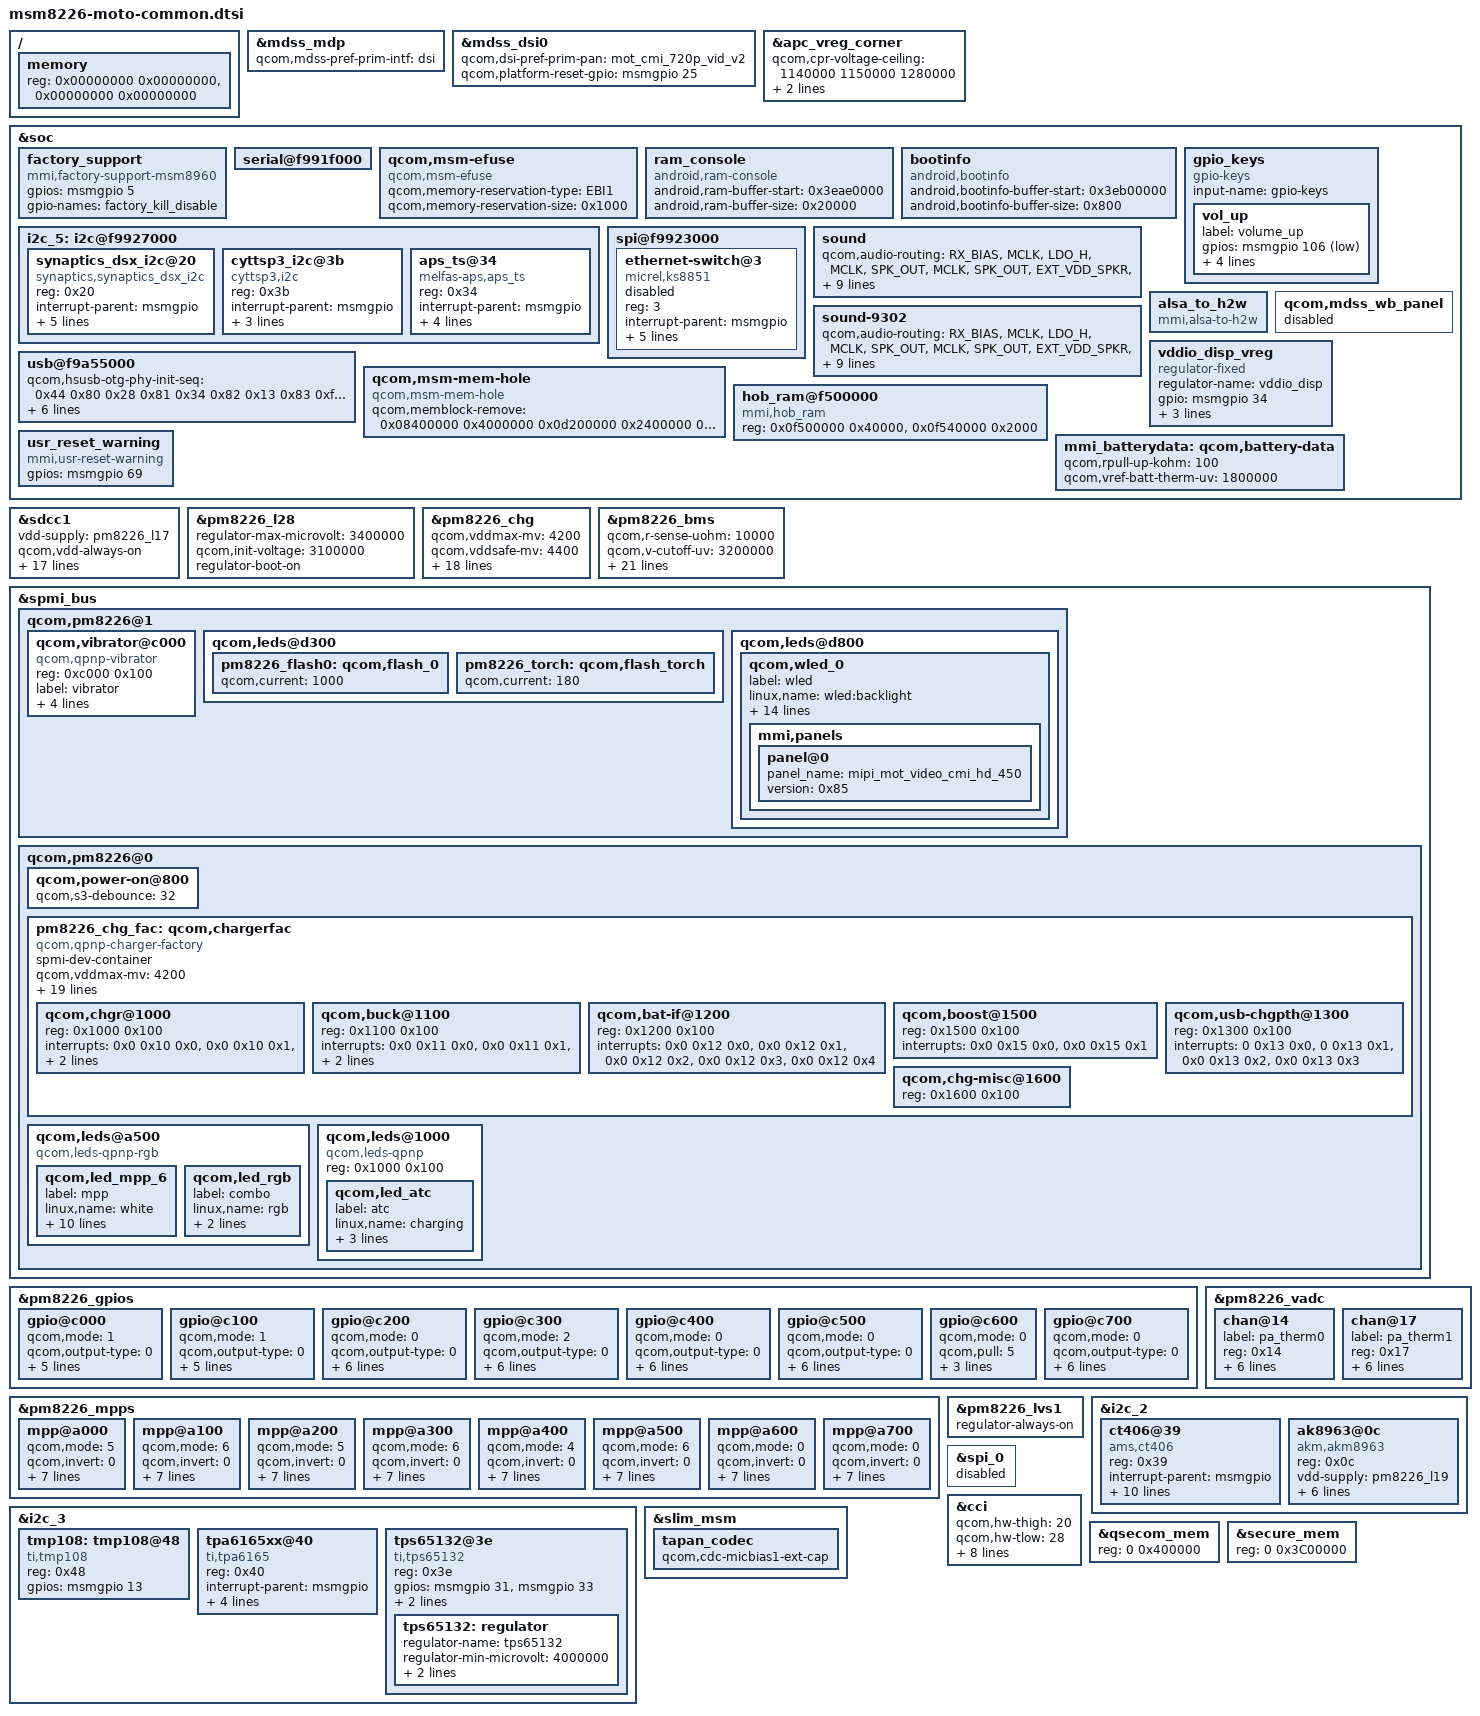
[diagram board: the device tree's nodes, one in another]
/* Copyright (c) 2013, The Linux Foundation. All rights reserved.
 * Copyright (c) 2013 Motorola Mobility LLC
 *
 * This program is free software; you can redistribute it and/or modify
 * it under the terms of the GNU General Public License version 2 and
 * only version 2 as published by the Free Software Foundation.
 *
 * This program is distributed in the hope that it will be useful,
 * but WITHOUT ANY WARRANTY; without even the implied warranty of
 * MERCHANTABILITY or FITNESS FOR A PARTICULAR PURPOSE.  See the
 * GNU General Public License for more details.
 */

/include/ "msm8226-moto-gpiomux.dtsi"
/include/ "carrier-channel-ids.dtsi"

/ {
	memory {
		reg = <0x00000000 0x00000000>,
		      <0x00000000 0x00000000>;
	};
};

&mdss_mdp {
	qcom,mdss-pref-prim-intf = "dsi";
};

&mdss_dsi0 {
	qcom,dsi-pref-prim-pan = <&mot_cmi_720p_vid_v2>;
};

&apc_vreg_corner {
	qcom,cpr-voltage-ceiling = <1140000 1150000 1280000>;
	qcom,cpr-voltage-floor = <1140000 1140000 1140000>;
};

&soc {
	factory_support {
		compatible = "mmi,factory-support-msm8960";

		gpios = <&msmgpio 5 0x2>; /* GPIOF_DIR_OUT | GPIOF_INIT_HIGH */
		gpio-names = "factory_kill_disable";
	};

	serial@f991f000 {
		status = "ok";
	};

	qcom,msm-efuse {
		compatible = "qcom,msm-efuse";
		qcom,memory-reservation-type = "EBI1";
		qcom,memory-reservation-size = <0x1000>; /* 4kb from EBI1 buffer */
	};

	ram_console {
		compatible = "android,ram-console";
		status = "ok";

		android,ram-buffer-start = <0x3eae0000>;
		android,ram-buffer-size = <0x20000>;
	};

	bootinfo {
		compatible = "android,bootinfo";

		android,bootinfo-buffer-start = <0x3eb00000>;
		android,bootinfo-buffer-size = <0x800>;
	};

	i2c_5: i2c@f9927000 {
		synaptics_dsx_i2c@20 {
			compatible = "synaptics,synaptics_dsx_i2c";
			reg = <0x20>;
			interrupt-parent = <&msmgpio>;
			interrupts = <17 0>;
			gpios = <&msmgpio 17 0>, /* IRQ */
				<&msmgpio 16 0>; /* RESET */
			touch_vdd-supply = <&pm8226_l28>;
			synaptics,normal-mode = <1>;
			synaptics,gpio-config;
		};

		cyttsp3_i2c@3b {
			compatible = "cyttsp3,i2c";
			reg = <0x3b>;
			interrupt-parent = <&msmgpio>;
			interrupts = <17 0x0>;
			vdd-supply = <&pm8226_l19>;
			vcc_i2c-supply = <&pm8226_lvs1>;
		};

		aps_ts@34 {
			compatible = "melfas-aps,aps_ts";
			reg = <0x34>;
			interrupt-parent = <&msmgpio>;
			interrupts = <17 0>;
			gpios = <&msmgpio 17 0>, /* IRQ */
				<&msmgpio 16 0>; /* RESET */
			aps_ts,default-product-id = "Falc";
			aps_ts,high-speed-isp;
		};
	};

	gpio_keys {
		compatible = "gpio-keys";
		input-name = "gpio-keys";

		vol_up {
			label = "volume_up";
			gpios = <&msmgpio 106 0x1>;
			linux,input-type = <1>;
			linux,code = <115>;
			gpio-key,wakeup;
			debounce-interval = <15>;
		};
	};

	spi@f9923000 {
		ethernet-switch@3 {
			status = "disabled";
			compatible = "micrel,ks8851";
			reg = <3>;
			interrupt-parent = <&msmgpio>;
			interrupts = <0 115 0>;
			spi-max-frequency = <4800000>;
			rst-gpio = <&msmgpio 114 0>;
			vdd-io-supply = <&pm8226_lvs1>;
			vdd-phy-supply = <&pm8226_lvs1>;
		};
	};

	sound {
		qcom,audio-routing =
			"RX_BIAS", "MCLK",
			"LDO_H", "MCLK",
			"SPK_OUT", "MCLK",
			"SPK_OUT", "EXT_VDD_SPKR",
			"AMIC1", "MIC BIAS1 External",
			"MIC BIAS1 External", "Handset Mic",
			"AMIC2", "MIC BIAS2 External",
			"MIC BIAS2 External", "Headset Mic",
			"AMIC3", "MIC BIAS1 External",
			"MIC BIAS1 External", "ANCRight Headset Mic",
			"AMIC4", "MIC BIAS2 External",
			"MIC BIAS2 External", "ANCLeft Headset Mic";

		qcom,cdc-mclk-gpios = <&pm8226_gpios 1 0>;
		qcom,cdc-vdd-spkr-gpios = <&pm8226_gpios 2 0>;
	};

	sound-9302 {
		qcom,audio-routing =
			"RX_BIAS", "MCLK",
			"LDO_H", "MCLK",
			"SPK_OUT", "MCLK",
			"SPK_OUT", "EXT_VDD_SPKR",
			"AMIC1", "MIC BIAS1 External",
			"MIC BIAS1 External", "Handset Mic",
			"AMIC2", "MIC BIAS2 External",
			"MIC BIAS2 External", "Headset Mic",
			"AMIC3", "MIC BIAS1 External",
			"MIC BIAS1 External", "ANCRight Headset Mic",
			"AMIC4", "MIC BIAS2 External",
			"MIC BIAS2 External", "ANCLeft Headset Mic";

		qcom,cdc-mclk-gpios = <&pm8226_gpios 1 0>;
		qcom,cdc-vdd-spkr-gpios = <&pm8226_gpios 2 0>;
	};

	usb@f9a55000 {
		qcom,hsusb-otg-phy-init-seq =
                        <0x44 0x80 0x28 0x81 0x34 0x82 0x13 0x83 0xffffffff>;
		qcom,hsusb-otg-mode = <3>;
		vbus_otg-supply = <&pm8226_chg_otg>;
		otg,id_flt_gpio = <&msmgpio 111 0x0>;
		otg,id_gnd_gpio = <&msmgpio 112 0x0>;
		id_flt_active_high = <1>;
		id_gnd_active_high = <1>;
	};

	alsa_to_h2w {
		compatible = "mmi,alsa-to-h2w";
	};

	qcom,mdss_wb_panel {
		status = "disabled";
	};

	vddio_disp_vreg: vddio_disp_vreg {
		compatible = "regulator-fixed";
		regulator-name = "vddio_disp";
		gpio = <&msmgpio 34 0x0>;
		parent-supply = <&pm8226_l8>;
		startup-delay-us = <300>;
		enable-active-high;
	};

	qcom,msm-mem-hole {
		compatible = "qcom,msm-mem-hole";
		qcom,memblock-remove = <0x08400000 0x4000000
					0x0d200000 0x2400000
					0x0fa00000 0x500000>; /* Address and Size of Hole */
	};

	hob_ram@f500000 {
		compatible = "mmi,hob_ram";
		reg = <0x0f500000 0x40000>,
		      <0x0f540000 0x2000>;
	};
	usr_reset_warning {
		compatible = "mmi,usr-reset-warning";
		gpios = <&msmgpio 69 0x0>;
	};

	mmi_batterydata: qcom,battery-data {
		qcom,rpull-up-kohm = <100>;
		qcom,vref-batt-therm-uv = <1800000>;

		/include/ "batterydata-ed30-temp.dtsi"
		/include/ "batterydata-ed30-sony.dtsi"
		/include/ "batterydata-ed30-sony-alt.dtsi"
		/include/ "batterydata-ed30-lg.dtsi"
	};
};

&sdcc1 {
	vdd-supply = <&pm8226_l17>;
	qcom,vdd-always-on;
	qcom,vdd-lpm-sup;
	qcom,vdd-voltage-level = <2950000 2950000>;
	qcom,vdd-current-level = <800 500000>;

	vdd-io-supply = <&pm8226_l6>;
	qcom,vdd-io-always-on;
	qcom,vdd-io-voltage-level = <1800000 1800000>;
	qcom,vdd-io-current-level = <250 154000>;

	qcom,pad-pull-on = <0x0 0x3 0x3>; /* no-pull, pull-up, pull-up */
	qcom,pad-pull-off = <0x0 0x3 0x3>; /* no-pull, pull-up, pull-up */
	qcom,pad-drv-on = <0x4 0x4 0x4>; /* 16mA, 10mA, 10mA */
	qcom,pad-drv-off = <0x0 0x0 0x0>; /* 2mA, 2mA, 2mA */

	qcom,clk-rates = <400000 25000000 50000000 100000000 200000000>;
	qcom,sup-voltages = <2950 2950>;

	qcom,bus-speed-mode = "HS200_1p8v", "DDR_1p8v";
	qcom,nonremovable;
	qcom,emmc;

	status = "ok";
};

&pm8226_l28 {
	regulator-max-microvolt = <3400000>;
	qcom,init-voltage = <3100000>;
	regulator-boot-on;
};

&pm8226_chg {
	qcom,vddmax-mv = <4200>;
	qcom,vddsafe-mv = <4400>;
	qcom,vinmin-mv = <4300>;
	qcom,vbatdet-delta-mv = <150>;
	qcom,ibatmax-ma = <2000>;
	qcom,ibatterm-ma = <100>;
	qcom,ibatsafe-ma = <3250>;
	qcom,thermal-mitigation = <1500 700 600 325>;
	qcom,tchg-mins = <512>;
	qcom,warm-bat-decidegc = <450>;
	qcom,cool-bat-decidegc = <0>;
	qcom,warm-bat-mv = <4000>;
	qcom,cool-bat-mv = <4000>;
	qcom,ibatmax-warm-ma = <2000>;
	qcom,ibatmax-cool-ma = <2000>;
	qcom,batt-hot-percentage = <25>;
	qcom,batt-cold-percentage = <80>;
	qcom,step-charge-voltage = <4200>;
	qcom,step-charge-current = <1130>;
	qcom,float-charge-timer = <1800>;
};

&pm8226_bms {
	qcom,r-sense-uohm = <10000>;
	qcom,v-cutoff-uv = <3200000>;
	qcom,max-voltage-uv = <4200000>;
	qcom,r-conn-mohm = <0>;
	qcom,shutdown-soc-valid-limit = <100>;
	qcom,adjust-soc-low-threshold = <15>;
	qcom,use-ocv-thresholds = <0>;
	qcom,low-soc-calculate-soc-threshold = <15>;
	qcom,low-soc-calculate-soc-ms = <5000>;
	qcom,calculate-soc-ms = <20000>;
	qcom,chg-term-ua = <100000>;
	qcom,batt-type = <0>;
	qcom,tm-temp-margin = <5000>;
	qcom,low-ocv-correction-limit-uv = <100>;
	qcom,high-ocv-correction-limit-uv = <50>;
	qcom,hold-soc-est = <3>;
	qcom,low-voltage-threshold = <3220000>;
	qcom,enable-fcc-learning = <1>;
	qcom,min-fcc-learning-soc = <20>;
	qcom,fcc-resolution = <10>;
	qcom,min-fcc-ocv-pc = <20>;
	qcom,min-fcc-learning-samples = <4>;
	qcom,battery-data = <&mmi_batterydata>;
};

&spmi_bus {
	qcom,pm8226@1 {
		qcom,vibrator@c000 {
			status = "okay";
			compatible = "qcom,qpnp-vibrator";
			reg = <0xc000 0x100>;
			label = "vibrator";
			qcom,vib-timeout-ms = <30000>;
			qcom,vib-vtg-level-mV = <1800>;
			qcom,vib-vtg-level-mV-haptic = <2800>;
			qcom,vib-boot-up-vibe-ms = <100>;
		};

		qcom,leds@d300 {
			status = "okay";
			pm8226_flash0: qcom,flash_0 {
				qcom,current = <1000>;
			};

			pm8226_torch: qcom,flash_torch {
				qcom,current = <180>;
			};
		};

		qcom,leds@d800 {
			status = "okay";
			qcom,wled_0 {
				label = "wled";
				linux,name = "wled:backlight";
				linux,default-trigger = "bkl-trigger";
				qcom,cs-out-en;
				qcom,op-fdbck = <1>;
				qcom,default-state = "off";
				qcom,max-current = <18>;
				qcom,ctrl-delay-us = <0>;
				qcom,boost-curr-lim = <0x03>;
				qcom,max-boost-duty = <0x02>;
				qcom,mod-scheme = <0x00>;
				qcom,cp-sel = <0>;
				qcom,switch-freq = <0x0b>;
				qcom,ovp-val = <2>;
				qcom,num-strings = <1>;
				qcom,id = <0>;
				mmi,panels {
					panel@0 {
						panel_name = "mipi_mot_video_cmi_hd_450";
						version = <0x85>;
					};
				};
			};
		};
	};

	qcom,pm8226@0 {

		qcom,power-on@800 {
			qcom,s3-debounce = <32>;
		};

		pm8226_chg_fac: qcom,chargerfac {
			spmi-dev-container;
			compatible = "qcom,qpnp-charger-factory";
			#address-cells = <1>;
			#size-cells = <1>;
			status = "ok";

			qcom,vddmax-mv = <4200>;
			qcom,vddsafe-mv = <4400>;
			qcom,vinmin-mv = <4300>;
			qcom,vbatdet-delta-mv = <150>;
			qcom,ibatmax-ma = <2000>;
			qcom,ibatterm-ma = <100>;
			qcom,ibatsafe-ma = <3250>;
			qcom,thermal-mitigation = <1500 700 600 325>;
			qcom,resume-soc = <99>;
			qcom,tchg-mins = <150>;
			qcom,chg-vadc = <&pm8226_vadc>;
			qcom,chg-adc_tm = <&pm8226_adc_tm>;
			qcom,ibatmax-warm-ma = <2000>;
			qcom,warm-bat-decidegc = <450>;
			qcom,warm-bat-mv = <4000>;
			qcom,cool-bat-decidegc = <10>;
			qcom,cool-bat-mv = <4000>;
			qcom,ibatmax-cool-ma = <2000>;
			qcom,batt-hot-percentage = <25>;
			qcom,batt-cold-percentage = <80>;

			qcom,chgr@1000 {
				status = "ok";
				reg = <0x1000 0x100>;
				interrupts =	<0x0 0x10 0x0>,
						<0x0 0x10 0x1>,
						<0x0 0x10 0x2>,
						<0x0 0x10 0x3>,
						<0x0 0x10 0x4>,
						<0x0 0x10 0x5>,
						<0x0 0x10 0x6>,
						<0x0 0x10 0x7>;

				interrupt-names =	"vbat-det-lo",
							"vbat-det-hi",
							"chgwdog",
							"state-change",
							"trkl-chg-on",
							"fast-chg-on",
							"chg-failed",
							"chg-done";
			};

			qcom,buck@1100 {
				status = "ok";
				reg = <0x1100 0x100>;
				interrupts =	<0x0 0x11 0x0>,
						<0x0 0x11 0x1>,
						<0x0 0x11 0x2>,
						<0x0 0x11 0x3>,
						<0x0 0x11 0x4>,
						<0x0 0x11 0x5>,
						<0x0 0x11 0x6>;

				interrupt-names =	"vbat-ov",
							"vreg-ov",
							"overtemp",
							"vchg-loop",
							"ichg-loop",
							"ibat-loop",
							"vdd-loop";
			};

			qcom,bat-if@1200 {
				status = "ok";
				reg = <0x1200 0x100>;
				interrupts =	<0x0 0x12 0x0>,
						<0x0 0x12 0x1>,
						<0x0 0x12 0x2>,
						<0x0 0x12 0x3>,
						<0x0 0x12 0x4>;

				interrupt-names =	"batt-pres",
							"bat-temp-ok",
							"bat-fet-on",
							"vcp-on",
							"psi";
			};

			qcom,boost@1500 {
				status = "ok";
				reg = <0x1500 0x100>;
				interrupts =	<0x0 0x15 0x0>,
						<0x0 0x15 0x1>;

				interrupt-names =	"boost-pwr-ok",
							"limit-error";
			};


			qcom,usb-chgpth@1300 {
				status = "ok";
				reg = <0x1300 0x100>;
				interrupts =	<0 0x13 0x0>,
						<0 0x13 0x1>,
						<0x0 0x13 0x2>,
						<0x0 0x13 0x3>;

				interrupt-names =	"coarse-det-usb",
							"usbin-valid",
							"chg-gone",
							"usb-ocp";
			};

			qcom,chg-misc@1600 {
				status = "ok";
				reg = <0x1600 0x100>;
			};
		};

		qcom,leds@a500 {
			compatible = "qcom,leds-qpnp-rgb";
			status = "okay";
			qcom,led_mpp_6 {
				label = "mpp";
				linux,name = "white";
				linux,default-trigger = "none";
				qcom,default-state = "off";
				qcom,max-current = <40>;
				qcom,current-setting = <5>;
				qcom,id = <6>;
				qcom,mode = "pwm";
				qcom,source-sel = <10>;
				qcom,mode-ctrl = <0x60>;
				qcom,pwm-channel = <5>;
				qcom,pwm-us = <1000>;
			};

		qcom,led_rgb {
				label = "combo";
				linux,name = "rgb";
				qcom,max-current = <12>;
				qcom,id = <9>;
			};
		};

		qcom,leds@1000 {
			status = "ok";
			reg = <0x1000 0x100>;
			compatible = "qcom,leds-qpnp";
			qcom,led_atc {
				label = "atc";
				linux,name = "charging";
				qcom,max-current = <40>;
				qcom,id = <8>;
				qcom,mode = <2>;
			};
		};
	};
};

&pm8226_gpios {
	gpio@c000 { /* GPIO 1 */
		/* XO_PMIC_CDC_MCLK enable for tapan codec */
		qcom,mode = <1>;		/* Digital output */
		qcom,output-type = <0>;	/* CMOS logic */
		qcom,pull = <5>;		/* QPNP_PIN_PULL_NO*/
		qcom,vin-sel = <2>;		/* QPNP_PIN_VIN2 */
		qcom,out-strength = <3>;/* QPNP_PIN_OUT_STRENGTH_HIGH */
		qcom,src-sel = <2>;		/* QPNP_PIN_SEL_FUNC_1 */
		qcom,master-en = <1>;	/* Enable GPIO */
	};

	gpio@c100 { /* GPIO 2 */
		qcom,mode = <1>;
		qcom,output-type = <0>;
		qcom,pull = <5>;
		qcom,vin-sel = <2>;
		qcom,out-strength = <3>;
		qcom,src-sel = <2>;
		qcom,master-en = <1>;
	};

	gpio@c200 { /* GPIO 3 */
		/* unused, force low power state */
		qcom,mode = <0>;
		qcom,output-type = <0>;
		qcom,invert = <0>;
		qcom,pull = <4>;
		qcom,vin-sel = <0>;
		qcom,out-strength = <1>;
		qcom,src-sel = <0>;
		qcom,master-en = <1>;
	};

	gpio@c300 { /* GPIO 4 */
		/* BATT_UIM_ALARM */
		qcom,mode = <2>;
		qcom,output-type = <0>;
		qcom,invert = <0>;
		qcom,pull = <4>;
		qcom,vin-sel = <3>;
		qcom,out-strength = <1>;
		qcom,src-sel = <2>;
		qcom,master-en = <1>;
	};

	gpio@c400 { /* GPIO 5 */
		/* unused, force low power state */
		qcom,mode = <0>;
		qcom,output-type = <0>;
		qcom,invert = <0>;
		qcom,pull = <4>;
		qcom,vin-sel = <0>;
		qcom,out-strength = <1>;
		qcom,src-sel = <0>;
		qcom,master-en = <1>;
	};

	gpio@c500 { /* GPIO 6 */
		/* LCD_CABC_WLED */
		qcom,mode = <0>;
		qcom,output-type = <0>;
		qcom,invert = <0>;
		qcom,pull = <5>;
		qcom,vin-sel = <3>;
		qcom,out-strength = <1>;
		qcom,src-sel = <2>;
		qcom,master-en = <1>;
	};

	gpio@c600 { /* GPIO 7 */
		/* TX_GTR_THRESH FUNC for PA_ON_NOFLASH */
		qcom,mode = <0>;		/* Digital input */
		qcom,pull = <5>;		/* QPNP_PIN_PULL_NO*/
		qcom,vin-sel = <3>;		/* QPNP_PIN_VIN3 L6 1.8V */
		qcom,src-sel = <2>;		/* QPNP_PIN_SEL_FUNC_1 */
		qcom,master-en = <1>;	/* Enable GPIO */
	};

	gpio@c700 { /* GPIO 8 */
		/* unused, force low power state */
		qcom,mode = <0>;
		qcom,output-type = <0>;
		qcom,invert = <0>;
		qcom,pull = <4>;
		qcom,vin-sel = <0>;
		qcom,out-strength = <1>;
		qcom,src-sel = <0>;
		qcom,master-en = <1>;
	};
};

&pm8226_mpps {
	mpp@a000 { /* MPP 1 */
		/* MSM_PX config */
		qcom,mode = <5>;
		qcom,invert = <0>;
		qcom,pull = <0>;
		qcom,vin-sel = <2>;
		qcom,src-sel = <1>;
		qcom,master-en = <1>;
		qcom,aout-ref = <0>;
		qcom,ain-route = <0>;
		qcom,cs-out = <0>;
	};

	mpp@a100 { /* MPP 2 */
		/* HR_LED_SINK config */
		qcom,mode = <6>;
		qcom,invert = <0>;
		qcom,pull = <0>;
		qcom,vin-sel = <0>;
		qcom,src-sel = <12>;
		qcom,master-en = <1>;
		qcom,aout-ref = <0>;
		qcom,ain-route = <0>;
		qcom,cs-out = <0>;
	};

	mpp@a200 { /* MPP 3 */
		/* VREF_LDO config */
		qcom,mode = <5>;
		qcom,invert = <0>;
		qcom,pull = <0>;
		qcom,vin-sel = <2>;
		qcom,src-sel = <1>;
		qcom,master-en = <1>;
		qcom,aout-ref = <0>;
		qcom,ain-route = <0>;
		qcom,cs-out = <0>;
	};

	mpp@a300 { /* MPP 4 */
		/* LED1_SINK config */
		qcom,mode = <6>;
		qcom,invert = <0>;
		qcom,pull = <0>;
		qcom,vin-sel = <0>;
		qcom,src-sel = <8>;
		qcom,master-en = <1>;
		qcom,aout-ref = <0>;
		qcom,ain-route = <0>;
		qcom,cs-out = <0>;
	};

	mpp@a400 { /* MPP 5 */
		/* PA_THERM0 config */
		qcom,mode = <4>;
		qcom,invert = <0>;
		qcom,pull = <0>;
		qcom,vin-sel = <0>;
		qcom,src-sel = <1>;
		qcom,master-en = <1>;
		qcom,aout-ref = <0>;
		qcom,ain-route = <0>;
		qcom,cs-out = <0>;
	};

	mpp@a500 { /* MPP 6 */
		/* LED2_SINK config */
		qcom,mode = <6>;
		qcom,invert = <0>;
		qcom,pull = <0>;
		qcom,vin-sel = <0>;
		qcom,src-sel = <10>;
		qcom,master-en = <1>;
		qcom,aout-ref = <0>;
		qcom,ain-route = <0>;
		qcom,cs-out = <0>;
	};

	mpp@a600 { /* MPP 7 */
		/* unused, force low power state */
		qcom,mode = <0>;
		qcom,invert = <0>;
		qcom,pull = <0>;
		qcom,vin-sel = <0>;
		qcom,src-sel = <0>;
		qcom,master-en = <0>;
		qcom,aout-ref = <0>;
		qcom,ain-route = <0>;
		qcom,cs-out = <0>;
	};

	mpp@a700 { /* MPP 8 */
		/* unused, force low power state */
		qcom,mode = <0>;
		qcom,invert = <0>;
		qcom,pull = <0>;
		qcom,vin-sel = <0>;
		qcom,src-sel = <0>;
		qcom,master-en = <0>;
		qcom,aout-ref = <0>;
		qcom,ain-route = <0>;
		qcom,cs-out = <0>;
	};
};

&pm8226_vadc {
	chan@14 {
		label = "pa_therm0";
		reg = <0x14>;
		qcom,decimation = <0>;
		qcom,pre-div-channel-scaling = <0>;
		qcom,calibration-type = "ratiometric";
		qcom,scale-function = <2>;
		qcom,hw-settle-time = <2>;
		qcom,fast-avg-setup = <0>;
	};

	chan@17 {
		label = "pa_therm1";
		reg = <0x17>;
		qcom,decimation = <0>;
		qcom,pre-div-channel-scaling = <0>;
		qcom,calibration-type = "ratiometric";
		qcom,scale-function = <2>;
		qcom,hw-settle-time = <2>;
		qcom,fast-avg-setup = <0>;
	};
};

&pm8226_lvs1 {
	regulator-always-on;
};

&i2c_2 {
	status = "ok";

	ct406@39 {
		compatible = "ams,ct406";
		reg = <0x39>;
		interrupt-parent = <&msmgpio>;
		interrupts = <65 0x2>;
		gpios = <&msmgpio 65 0>; /* IRQ */
		vdd-supply = <&pm8226_l19>;
		ams,prox-samples-for-noise-floor = <0x05>;
		ams,prox-covered-offset = <0x0096>;
		ams,prox-uncovered-offset = <0x006e>;
		ams,prox-recalibrate-offset = <0x0046>;
		ams,prox-offset = <0x00>;
		ams,prox-pulse-count = <0x04>;
		ams,ink_type = <0x01>;
	};

	ak8963@0c {
		compatible = "akm,akm8963";
		reg = <0x0c>;
		vdd-supply = <&pm8226_l19>;
		interrupt-parent = <&msmgpio>;
		interrupts = <66 0x2>;
		akm,gpio-irq = <&msmgpio 66 0>;
		akm,gpio-rst = <&msmgpio 62 0>;
		akm,outbit = <1>;
		akm,layout = <6>;
	};
};

&i2c_3 {
	status = "ok";

	tmp108: tmp108@48 {
		compatible = "ti,tmp108";
		reg = <0x48>;
		gpios = <&msmgpio 13 0>;
	};


	tpa6165xx@40 {
		compatible = "ti,tpa6165";
		reg = <0x40>;
		interrupt-parent = <&msmgpio>;
		interrupts = <4 0x2>;
		gpios = <&msmgpio 4 0x0>;
		hs_det_vdd-supply = <&pm8226_l6>;
		hs_det_micvdd-supply = <&pm8226_l21>;
	};

	tps65132@3e {
		compatible = "ti,tps65132";
		reg = <0x3e>;
		gpios = <&msmgpio 31 0x0>, <&msmgpio 33 0x0>;
		active-dis;
		bias-delay-us = <2000>;
		tps65132: regulator {
			regulator-name = "tps65132";
			regulator-min-microvolt = <4000000>;
			regulator-max-microvolt = <6000000>;
			startup-delay-us = <10000>;
		};
	};
};

&slim_msm {
	tapan_codec {
		qcom,cdc-micbias1-ext-cap;
	};
};

&mdss_dsi0 {
	qcom,platform-reset-gpio = <&msmgpio 25 0>;
};

&spi_0 {
	status = "disabled";
};

&cci {
	qcom,hw-thigh = <20>;
	qcom,hw-tlow = <28>;
	qcom,hw-tsu-sto = <21>;
	qcom,hw-tsu-sta = <21>;
	qcom,hw-thd-dat = <13>;
	qcom,hw-thd-sta = <18>;
	qcom,hw-tbuf = <25>;
	qcom,hw-scl-stretch-en = <0>;
	qcom,hw-trdhld = <6>;
	qcom,hw-tsp = <3>;
};

&qsecom_mem {
	reg = <0 0x400000>;
};

&secure_mem {
	reg = <0 0x3C00000>;
};
